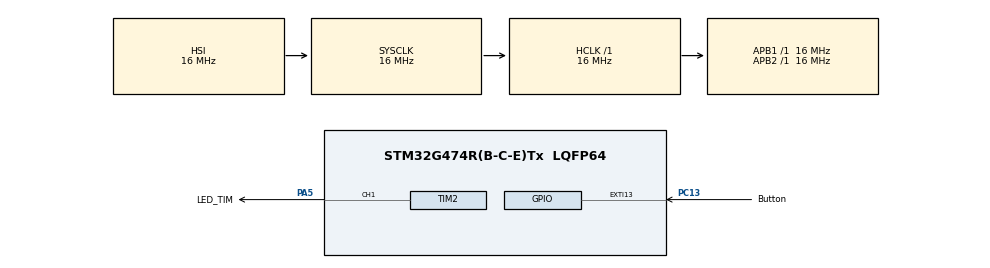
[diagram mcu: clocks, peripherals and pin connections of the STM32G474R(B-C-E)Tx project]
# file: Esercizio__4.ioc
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Mcu.Family=STM32G4
Mcu.Name=STM32G474R(B-C-E)Tx
Mcu.Package=LQFP64
NVIC.EXTI15_10_IRQn=true\:0\:0\:false\:false\:true\:true\:true\:true
NVIC.PriorityGroup=NVIC_PRIORITYGROUP_4
NVIC.TIM2_IRQn=true\:0\:0\:false\:false\:true\:true\:true\:true
PA5.GPIO_Label=LED_TIM
PA5.Signal=S_TIM2_CH1
PC13.GPIO_Label=Button
PC13.Signal=GPXTI13
ProjectManager.HeapSize=0x200
ProjectManager.StackSize=0x400
ProjectManager.TargetToolchain=STM32CubeIDE
RCC.AHBFreq_Value=16000000
RCC.APB1Freq_Value=16000000
RCC.APB1TimFreq_Value=16000000
RCC.APB2Freq_Value=16000000
RCC.APB2TimFreq_Value=16000000
RCC.CortexFreq_Value=16000000
RCC.EXTERNAL_CLOCK_VALUE=12288000
RCC.HCLKFreq_Value=16000000
RCC.HSE_VALUE=8000000
RCC.HSI48_VALUE=48000000
RCC.HSI_VALUE=16000000
RCC.LSE_VALUE=32768
RCC.SYSCLKFreq_VALUE=16000000
RCC.USBFreq_Value=64000000
RCC.VCOOutputFreq_Value=128000000
SH.S_TIM2_CH1.0=TIM2_CH1,Output Compare1 CH1
TIM2.Channel-Output\ Compare1\ CH1=TIM_CHANNEL_1
TIM2.OCMode_1=TIM_OCMODE_TOGGLE
TIM2.PeriodNoDither=999
TIM2.Prescaler=15999
VP_SYS_VS_DBSignals.Mode=DisableDeadBatterySignals
board=custom

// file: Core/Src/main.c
/* USER CODE BEGIN Header */
/**
  ******************************************************************************
  * @file           : main.c
  * @brief          : Main program body
  ******************************************************************************
  * @attention
  *
  * Copyright (c) 2025 STMicroelectronics.
  * All rights reserved.
  *
  * This software is licensed under terms that can be found in the LICENSE file
  * in the root directory of this software component.
  * If no LICENSE file comes with this software, it is provided AS-IS.
  *
  ******************************************************************************
  */
/* USER CODE END Header */
#include "main.h"
#include "tim.h"
#include "gpio.h"

/* USER CODE BEGIN PTD */
typedef enum{
	ONE_HZ,
	TWO_HZ,
	FOUR_HZ
}State;

/* USER CODE END PTD */

/* USER CODE BEGIN PV */
State currentState = ONE_HZ;
/* USER CODE END PV */

void SystemClock_Config(void);

int main(void)
{

  /* MCU Configuration--------------------------------------------------------*/

  /* Reset of all peripherals, Initializes the Flash interface and the Systick. */
  HAL_Init();

  /* Configure the system clock */
  SystemClock_Config();

  /* Initialize all configured peripherals */
  MX_GPIO_Init();
  MX_TIM2_Init();
  /* USER CODE BEGIN 2 */
  HAL_TIM_OC_Start(&htim2, TIM_CHANNEL_1);
  /* USER CODE END 2 */

  /* Infinite loop */
  while (1)
  {

  }
}

void SystemClock_Config(void)
{
  RCC_OscInitTypeDef RCC_OscInitStruct = {0};
  RCC_ClkInitTypeDef RCC_ClkInitStruct = {0};

  /** Configure the main internal regulator output voltage
  */
  HAL_PWREx_ControlVoltageScaling(PWR_REGULATOR_VOLTAGE_SCALE1);

  /** Initializes the RCC Oscillators according to the specified parameters
  * in the RCC_OscInitTypeDef structure.
  */
  RCC_OscInitStruct.OscillatorType = RCC_OSCILLATORTYPE_HSI;
  RCC_OscInitStruct.HSIState = RCC_HSI_ON;
  RCC_OscInitStruct.HSICalibrationValue = RCC_HSICALIBRATION_DEFAULT;
  RCC_OscInitStruct.PLL.PLLState = RCC_PLL_NONE;
  if (HAL_RCC_OscConfig(&RCC_OscInitStruct) != HAL_OK)
  {
    Error_Handler();
  }

  /** Initializes the CPU, AHB and APB buses clocks
  */
  RCC_ClkInitStruct.ClockType = RCC_CLOCKTYPE_HCLK|RCC_CLOCKTYPE_SYSCLK
                              |RCC_CLOCKTYPE_PCLK1|RCC_CLOCKTYPE_PCLK2;
  RCC_ClkInitStruct.SYSCLKSource = RCC_SYSCLKSOURCE_HSI;
  RCC_ClkInitStruct.AHBCLKDivider = RCC_SYSCLK_DIV1;
  RCC_ClkInitStruct.APB1CLKDivider = RCC_HCLK_DIV1;
  RCC_ClkInitStruct.APB2CLKDivider = RCC_HCLK_DIV1;

  if (HAL_RCC_ClockConfig(&RCC_ClkInitStruct, FLASH_LATENCY_0) != HAL_OK)
  {
    Error_Handler();
  }
}

/* USER CODE BEGIN 4 */
void HAL_GPIO_EXTI_Callback(uint16_t GPIO_Pin){
	/* Alla pressione del bottone PC13, si deve cambiare frequenza del blinking led
	 *
	 * Formula per updateEvent del timer: UEV = clock/[(Prescaler + 1)(AutoReloadRegister + 1)]
	 *
	 * Dal file .ioc è stato imposto clock = 16MHz, Prescaler 15999, ARR = 999 =>   UEV = 1Hz quando l'applicazione parte
	 *
	 * In base allo stato in cui ci si trova, per cambiare l'UEV:
	 * - o si modifica l'AutoReloadRegister ARR (Counter Period),
	 * - o si modifica il Prescaler PSC
	 *
	 * */
	if(GPIO_Pin == Button_Pin){
		switch(currentState){

		case ONE_HZ:
			/* 		Modifico ARR
			 *
			 * htim2.Instance->ARR = 499; // __HAL_TIM_SET_AUTORELOAD(&htim2, 499);
			 * htim2.Instance->CNT = 0;   // __HAL_TIM_SET_COUNTER(&htim2, 0);
			 * currentState = TWO_HZ;
			 *
			 */

			/* Modifico PSC */
			htim2.Instance->PSC = 7999; // __HAL_TIM_SET_PRESCALER(&htim2, 7999);
			currentState = TWO_HZ;
			break;

		case TWO_HZ:
			/* 		Modifico ARR
			 *
			 * htim2.Instance->ARR = 249; // __HAL_TIM_SET_AUTORELOAD(&htim2, 249);
			 * htim2.Instance->CNT = 0;   // __HAL_TIM_SET_COUNTER(&htim2, 0);
			 * currentState = FOUR_HZ;
			 *
			 */

			/* Modifico PSC */
			htim2.Instance->PSC = 3999;  // __HAL_TIM_SET_PRESCALER(&htim2, 3999);
			currentState = FOUR_HZ;

			__HAL_TIM_SET_AUTORELOAD
			__HAL_TIM_GET_AUTORELOAD
			__HAL_TIM_SET_PRESCALER
			break;

		case FOUR_HZ:
			/* 		Modifico ARR
			 *
			 * htim2.Instance->ARR = 999; // __HAL_TIM_SET_AUTORELOAD(&htim2, 999);
			 * htim2.Instance->CNT = 0;   // __HAL_TIM_SET_COUNTER(&htim2, 0);
			 * currentState = ONE_HZ;
			 *
			 */

			/* Modifico PSC */
			htim2.Instance->PSC = 15999; // __HAL_TIM_SET_PRESCALER(&htim2, 15999);
			currentState = ONE_HZ;
			break;
		}
	}
}
/* USER CODE END 4 */

void Error_Handler(void)
{
  __disable_irq();
  while (1)
  {
  }
}
